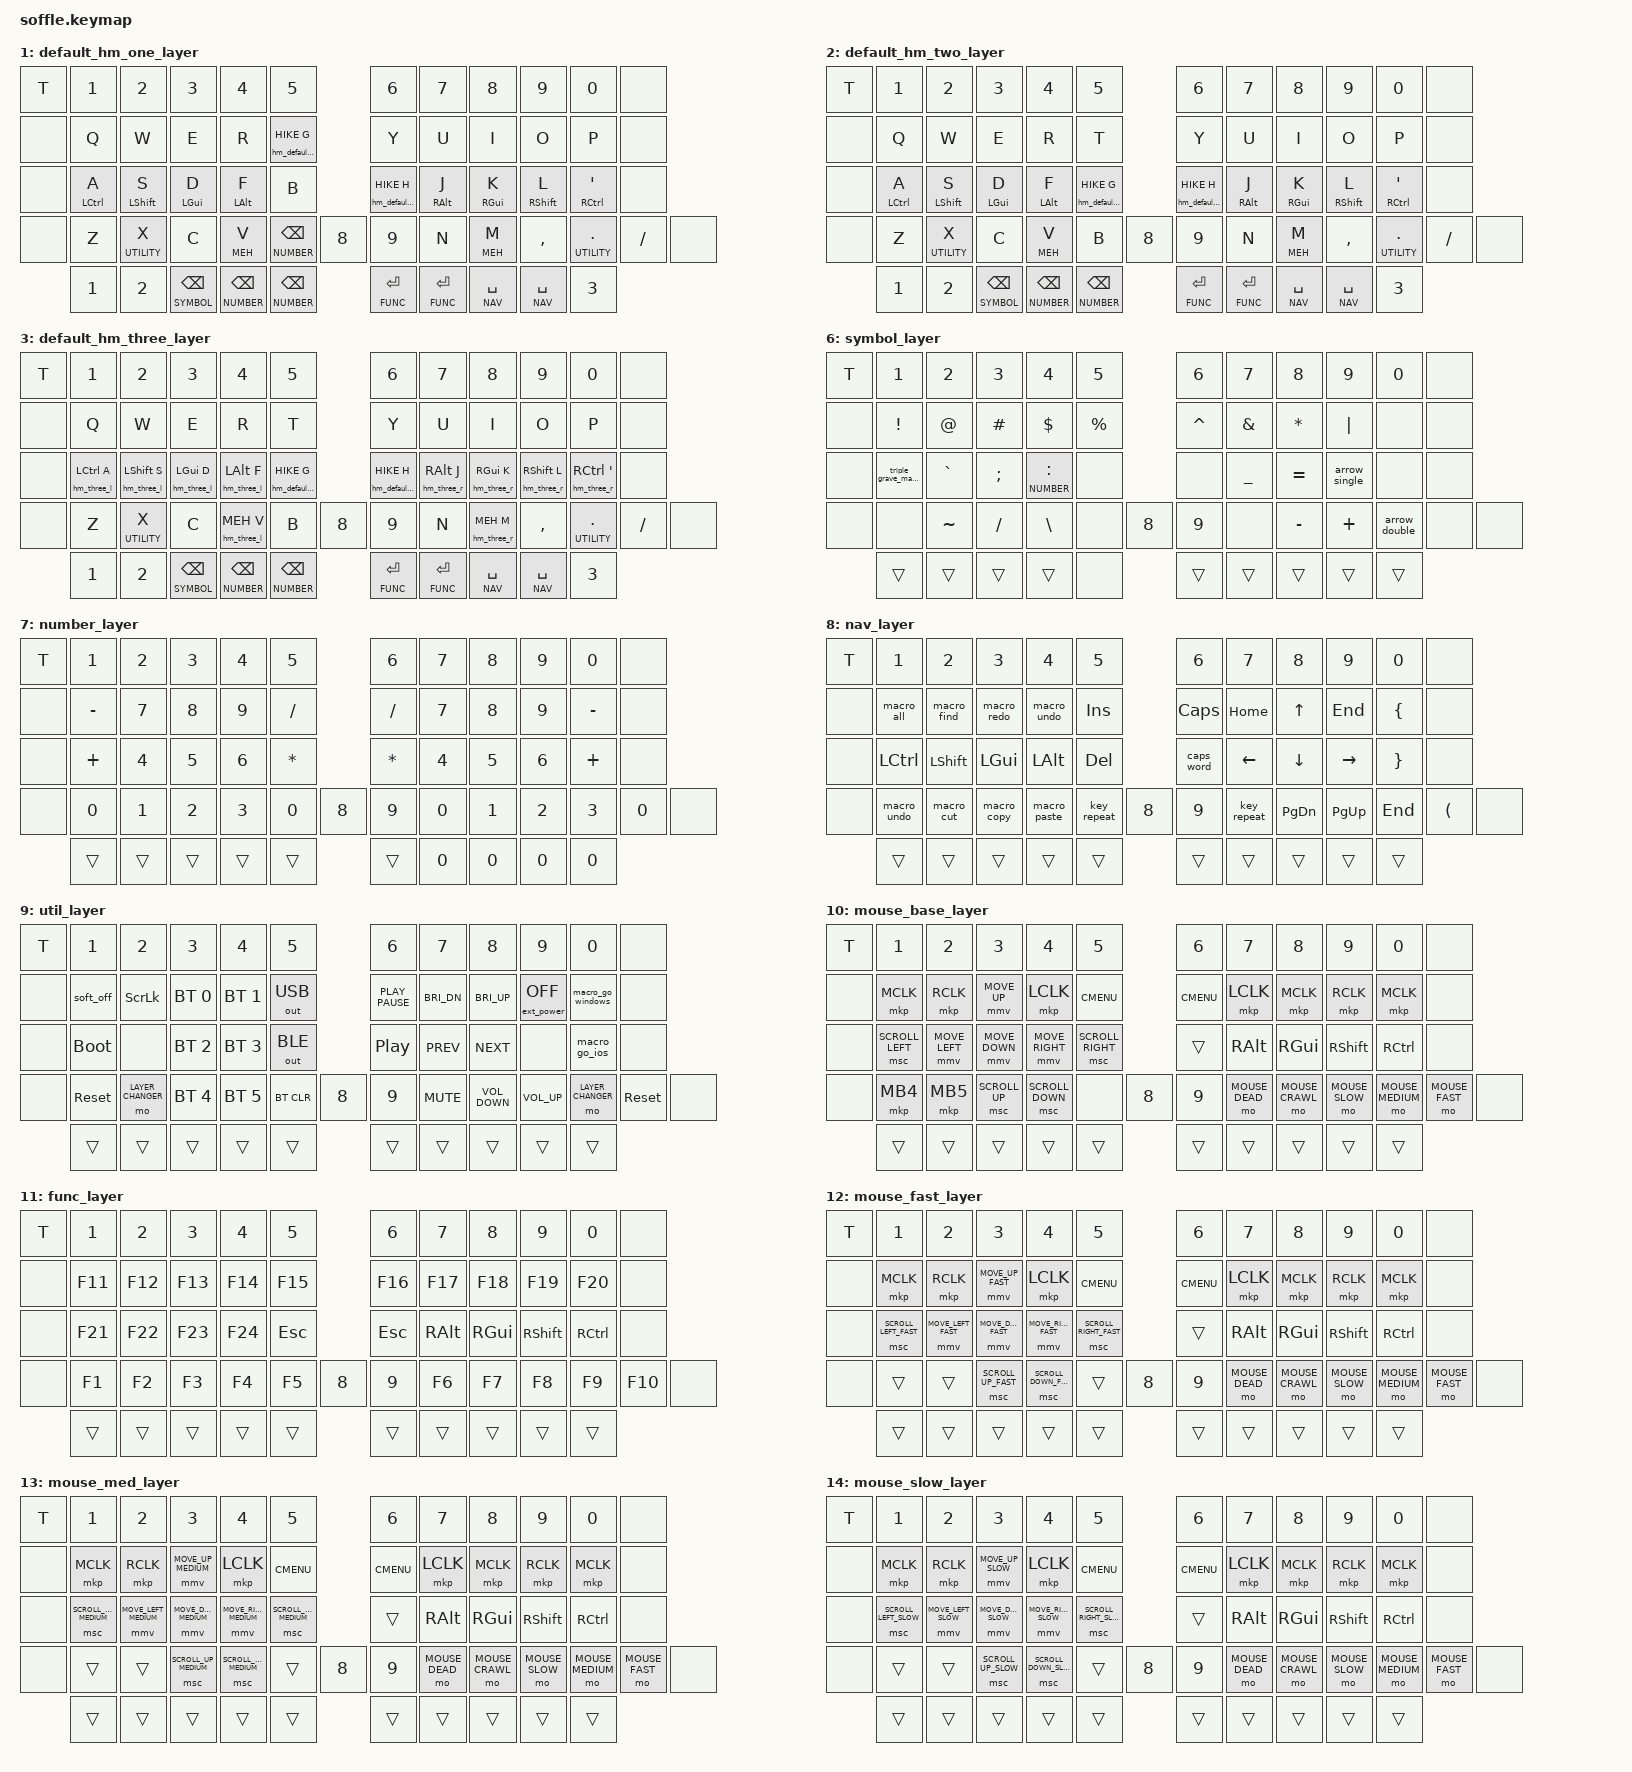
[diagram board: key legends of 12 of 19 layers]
/*
 * Copyright (c) 2020 The ZMK Contributors 
 *
 * SPDX-License-Identifier: MIT
 */

#include <behaviors.dtsi>
#include <behaviors/mouse_keys.dtsi>
#include <dt-bindings/zmk/mouse.h>
#include <dt-bindings/zmk/keys.h>
#include <dt-bindings/zmk/bt.h>
#include <dt-bindings/zmk/outputs.h>
#include <dt-bindings/zmk/ext_power.h>

#include "keymap_mouse.h"
#include "base_configs.h"




/ {
        conditional_layers {
            compatible = "zmk,conditional-layers";
            tri_layer {
                    if-layers = <SYMBOL NAV>;
                    then-layer = <MOUSE_BASE>;
            };
            
             tri_layer_two {
                     if-layers = <FUNC NAV>;
                     then-layer = <CONVENIENCE_LAYER>;
             };

             tri_layer_three {
                     if-layers = <FUNC NUMBER>;
                     then-layer = <CONVENIENCE_LAYER>;
             };
        };

        macros {
            #include "macros.dtsi"
        };
        
        combos {
            #include "combos.dtsi"
        }; 

        behaviors {
            #include "user_behaviors.dtsi"
        };

        keymap {
                compatible = "zmk,keymap";

        default_layer {
                          bindings = < LAYER_FROM64( \
&kp ESCAPE,  &kp B,       &kp N2,       &kp N3,        &kp N4,             &kp N5,                                          &kp N6,             &kp N7,              &kp N8,        &kp N9,       &kp N0,          &kp BACKSPACE,
&kp TAB,     &kp C,        &kp W,        &kp E,         &kp R,              &kp T,                                           &kp Y,              &kp U,               &kp I,         &kp O,        &kp P,           &kp DEL,
&kp LCTRL,   &kp D,  &hrm LALT S,  &hrm LCTRL D,  &hrm LEFT_SHIFT F,  &kp G,                                           &kp H,              &hrm RIGHT_SHIFT J,  &hrm RCTRL K,  &hrm RALT L,  &hrm RGUI SEMI,  &kp SQT,
&kp LSHFT,   &kp Z,        &kp X,        &kp C,         &kp V,              &kp B,          &tog GAME,      &kp C_MUTE,      &kp N,              &kp M,               &kp COMMA,     &kp DOT,      &kp FSLH,        &kp RSHFT,
&kp LCTRL,   &kp LALT,     &trans,       &trans,        &lt NUM ESCAPE,     &lt MOUSE SPACE,&lt MACRO TAB,  &lt SYMBOL ENTER,&lt NAV BACKSPACE,  &lt FUNC DEL,        &trans,        &trans,       &kp F13,         &kp F14
            )>;

            sensor-bindings = <&inc_dec_kp LC(Y) LC(Z) &inc_dec_kp C_VOLUME_UP C_VOL_DN>;
        };

                default_hm_one_layer {												
                        bindings = <											 
        &kp T               	&kp N1              	&kp N2              	&kp N3              	&kp N4              	&kp N5              		                    	&kp N6              	&kp N7              	&kp N8              	&kp N9              	&kp N0              	&none               
        &none               	&kp Q               	&kp W               	&kp E               	&kp R               	&hm_default_l HIKE G		                    	&kp Y               	&kp U               	&kp I               	&kp O               	&kp P               	&none               
        &none               	&hm_one_l LCTRL A   	&hm_one_l LSHFT S   	&hm_one_l LGUI D    	&hm_one_l LALT F    	&kp B               	 	                    	&hm_default_r HIKE H	&hm_one_r RALT J    	&hm_one_r RGUI K    	&hm_one_r RSHFT L   	&hm_one_r RCTRL APOS	&none               
        &none               	&kp Z               	&lt UTILITY X       	&kp C               	&hm_one_l MEH V     	&lt NUMBER BSPC     	&kp N8              	&kp N9              	&kp N               	&hm_one_r MEH M     	&kp COMMA           	&lt UTILITY DOT     	&kp FSLH            	&none               
                                &kp N1              	&kp N2              	&lt SYMBOL BSPC     	&lt NUMBER BSPC     	&lt NUMBER BSPC     		                    	&lt FUNC ENTER      	&lt FUNC ENTER      	&lt NAV SPACE       	&lt NAV SPACE       	&kp N3              	                    
                >; sensor-bindings = <&inc_dec_kp UP DOWN &inc_dec_kp LC(LEFT)  >; };												
                default_hm_two_layer {												
                        bindings = <											
        &kp T               	&kp N1              	&kp N2              	&kp N3              	&kp N4              	&kp N5              		                    	&kp N6              	&kp N7              	&kp N8              	&kp N9              	&kp N0              	&none               
        &none               	&kp Q               	&kp W               	&kp E               	&kp R               	&kp T               		                    	&kp Y               	&kp U               	&kp I               	&kp O               	&kp P               	&none               
        &none               	&hm_two_l LCTRL A   	&hm_two_l LSHFT S   	&hm_two_l LGUI D    	&hm_two_l LALT F    	&hm_default_l HIKE G	  	                    	&hm_default_r HIKE H	&hm_two_r RALT J    	&hm_two_r RGUI K    	&hm_two_r RSHFT L   	&hm_two_r RCTRL APOS	&none               
        &none               	&kp Z               	&lt UTILITY X       	&kp C               	&hm_two_l MEH V     	&kp B               	&kp N8              	&kp N9              	&kp N               	&hm_two_r MEH M     	&kp COMMA           	&lt UTILITY DOT     	&kp FSLH            	&none               
                &kp N1              	&kp N2              	&lt SYMBOL BSPC     	&lt NUMBER BSPC     	&lt NUMBER BSPC     			&lt FUNC ENTER      	&lt FUNC ENTER      	&lt NAV SPACE       	&lt NAV SPACE       	&kp N3              	                    
                >; sensor-bindings = <&inc_dec_kp UP DOWN &inc_dec_kp LC(LEFT)  >; };												
                default_hm_three_layer {												
                        bindings = <											
        &kp T                 	&kp N1                	&kp N2                	&kp N3                	&kp N4                	&kp N5                			&kp N6                	&kp N7                	&kp N8                	&kp N9                	&kp N0                	&none                 
        &none                 	&kp Q                 	&kp W                 	&kp E                 	&kp R                 	&kp T                 			&kp Y                 	&kp U                 	&kp I                 	&kp O                 	&kp P                 	&none                 
        &none                 	&hm_three_l LCTRL A   	&hm_three_l LSHFT S   	&hm_three_l LGUI D    	&hm_three_l LALT F    	&hm_default_l HIKE G  	   	   	&hm_default_r HIKE H  	&hm_three_r RALT J    	&hm_three_r RGUI K    	&hm_three_r RSHFT L   	&hm_three_r RCTRL APOS	&none                 
        &none                 	&kp Z                 	&lt UTILITY X         	&kp C                 	&hm_three_l MEH V     	&kp B                 	&kp N8                	&kp N9                	&kp N                 	&hm_three_r MEH M     	&kp COMMA             	&lt UTILITY DOT       	&kp FSLH              	&none                 
                                &kp N1                	&kp N2                	&lt SYMBOL BSPC       	&lt NUMBER BSPC       	&lt NUMBER BSPC       			&lt FUNC ENTER        	&lt FUNC ENTER        	&lt NAV SPACE         	&lt NAV SPACE         	&kp N3                	                      
                >; sensor-bindings = <&inc_dec_kp UP DOWN &inc_dec_kp LC(LEFT)  >; };												
                default_hm_none_layer {												
                        bindings = <											
        &kp T                	&kp N1               	&kp N2               	&kp N3               	&kp N4               	&kp N5               			&kp N6               	&kp N7               	&kp N8               	&kp N9               	&kp N0               	&none                
                                &kp Q                	&kp W                	&kp E                	&kp R                	&kp T                			&kp Y                	&kp U                	&kp I                	&kp O                	&kp P                	&none                
                                &hm_four_l LCTRL A   	&kp S                	&kp D                	&kp F                	&hm_default_l HIKE G 	    	    	&hm_default_r HIKE H 	&kp J                	&kp K                	&kp L                	&hm_four_r RCTRL APOS	&none                
                                &kp Z                	&lt UTILITY X        	&kp C                	&hm_four_l MEH V     	&kp B                	&kp N8               	&kp N9               	&kp N                	&hm_four_r MEH M     	&kp COMMA            	&lt UTILITY DOT      	&kp FSLH             	&none                
                                &kp N1               	&kp N2               	&lt SYMBOL BSPC      	&lt NUMBER BSPC      	&lt NUMBER BSPC      			&lt FUNC ENTER       	&lt FUNC ENTER       	&lt NAV SPACE        	&lt NAV SPACE        	&kp N3               	                     
                >; sensor-bindings = <&inc_dec_kp UP DOWN &inc_dec_kp LC(LEFT)  >; };												
                default_ios_layer {												
                        bindings = <											
        &kp T                   	&kp N1                  	&kp N2                  	&kp N3                  	&kp N4                  	&kp N5                  			&kp N6                  	&kp N7                  	&kp N8                  	&kp N9                  	&kp N0                  	&none                   
        &none                   	&kp Q                   	&kp W                   	&kp E                   	&kp R                   	&kp T                   			&kp Y                   	&kp U                   	&kp I                   	&kp O                   	&kp P                   	
        &none                   	&hm_default_l LGUI A    	&hm_default_l LSHFT S   	&hm_default_l LCTRL D   	&hm_default_l LALT F    	&hm_default_l HIKE G    	     	     	&hm_default_r HIKE H    	&hm_default_r RALT J    	&hm_default_r RCTRL K   	&hm_default_r RSHFT L   	&hm_default_r RGUI APOS 	
        &none                   	&hm_default_l LSHFT Z   	&lt UTILITY X           	&kp C                   	&hm_default_l MEH V     	&kp B                   	&kp N8                  	&kp N9                  	&kp N                   	&hm_default_r MEH M     	&kp COMMA               	&lt UTILITY DOT         	&hm_default_r LSHFT FSLH	
                                        &kp N1                  	&kp N2                  	&lt SYMBOL BSPC         	&lt NUMBER BSPC         	&lt NUMBER BSPC         			&lt FUNC ENTER          	&lt FUNC ENTER          	&lt NAV SPACE           	&lt NAV SPACE           	&kp N3                  	
                >; sensor-bindings = <&inc_dec_kp UP DOWN &inc_dec_kp LC(LEFT)  >; };												
                symbol_layer {												
                        bindings = <											
        &kp T              	&kp N1             	&kp N2             	&kp N3             	&kp N4             	&kp N5             			&kp N6             	&kp N7             	&kp N8             	&kp N9             	&kp N0             	&none              
        &none              	&kp EXCL           	&kp AT             	&kp HASH           	&kp DOLLAR         	&kp PERCENT        			&kp CARET          	&kp AMPS           	&kp STAR           	&kp PIPE           	&none              	&none              
        &none              	&triple_grave_macro	&kp GRAVE          	&kp SEMI           	&lt NUMBER COLON   	&none              	     	     	&none              	&kp UNDER          	&kp EQUAL          	&arrow_single      	&none              	&none              
        &none              	&none              	&kp TILDE          	&kp FSLH           	&kp BSLH           	&none              	&kp N8             	&kp N9             	&none              	&kp MINUS          	&kp PLUS           	&arrow_double      	&none              	&none              
                                &trans             	&trans             	&trans             	&trans             	&none              			&trans             	&trans             	&trans             	&trans             	&trans             	                   
                >; sensor-bindings = <&inc_dec_kp UP DOWN &inc_dec_kp LC(LEFT)  >; };												
                number_layer {												
                        bindings = <											
        &kp T    	&kp N1   	&kp N2   	&kp N3   	&kp N4   	&kp N5   			&kp N6   	&kp N7   	&kp N8   	&kp N9   	&kp N0   	&none    
        &none    	&kp MINUS	&kp N7   	&kp N8   	&kp N9   	&kp FSLH 			&kp FSLH 	&kp N7   	&kp N8   	&kp N9   	&kp MINUS	&none    
        &none    	&kp PLUS 	&kp N4   	&kp N5   	&kp N6   	&kp STAR 	      	      	&kp STAR 	&kp N4   	&kp N5   	&kp N6   	&kp PLUS 	&none    
        &none    	&kp N0   	&kp N1   	&kp N2   	&kp N3   	&kp N0   	&kp N8   	&kp N9   	&kp N0   	&kp N1   	&kp N2   	&kp N3   	&kp N0   	&none    
                        &trans   	&trans   	&trans   	&trans   	&trans   			&trans   	&kp N0   	&kp N0   	&kp N0   	&kp N0   	         
                >; sensor-bindings = <&inc_dec_kp UP DOWN &inc_dec_kp LC(LEFT)  >; };												
                nav_layer {												
                        bindings = <											
        &kp T       	&kp N1      	&kp N2      	&kp N3      	&kp N4      	&kp N5      			&kp N6      	&kp N7      	&kp N8      	&kp N9      	&kp N0      	&none       
        &none       	&macro_all  	&macro_find 	&macro_redo 	&macro_undo 	&kp INS     			&kp CAPS    	&kp HOME    	&kp UP      	&kp END     	&kp LBRC    	&none       
        &none       	&kp LCTRL   	&kp LSHFT   	&kp LGUI    	&kp LALT    	&kp DEL     	       	       	&caps_word  	&kp LEFT    	&kp DOWN    	&kp RIGHT   	&kp RBRC    	&none       
        &none       	&macro_undo 	&macro_cut  	&macro_copy 	&macro_paste	&key_repeat 	&kp N8      	&kp N9      	&key_repeat 	&kp PG_DN   	&kp PG_UP   	&kp END     	&kp LPAR    	&none       
                        &trans      	&trans      	&trans      	&trans      	&trans      			&trans      	&trans      	&trans      	&trans      	&trans      	            
                >; sensor-bindings = <&inc_dec_kp UP DOWN &inc_dec_kp LC(LEFT)  >; };												
                util_layer {												
                        bindings = <											
        &kp T            	&kp N1           	&kp N2           	&kp N3           	&kp N4           	&kp N5           			&kp N6           	&kp N7           	&kp N8           	&kp N9           	&kp N0           	&none            
        &none            	&soft_off        	&kp SLCK         	&bt BT_SEL 0     	&bt BT_SEL 1     	&out OUT_USB     			&kp K_PLAY_PAUSE 	&kp C_BRI_DN     	&kp C_BRI_UP     	&ext_power EP_OFF	&macro_go_windows	&none            
        &none            	&bootloader      	&none            	&bt BT_SEL 2     	&bt BT_SEL 3     	&out OUT_BLE     	        	        	&kp C_PLAY_PAUSE 	&kp C_PREV       	&kp C_NEXT       	&none            	&macro_go_ios    	&none            
        &none            	&sys_reset       	&mo LAYER_CHANGER	&bt BT_SEL 4     	&bt BT_SEL 5     	&bt BT_CLR       	&kp N8           	&kp N9           	&kp C_MUTE       	&kp C_VOLUME_DOWN	&kp C_VOLUME_UP  	&mo LAYER_CHANGER	&sys_reset       	&none            
                                &trans           	&trans           	&trans           	&trans           	&trans           			&trans           	&trans           	&trans           	&trans           	&trans           	                 
                >; sensor-bindings = <&inc_dec_kp UP DOWN &inc_dec_kp LC(LEFT)  >; };												
                mouse_base_layer {												
                        bindings = <											
        &kp T            	&kp N1           	&kp N2           	&kp N3           	&kp N4           	&kp N5           			&kp N6           	&kp N7           	&kp N8           	&kp N9           	&kp N0           	&none            
        &none            	&mkp MCLK        	&mkp RCLK        	&mmv MOVE_UP     	&mkp LCLK        	&kp K_CMENU      			&kp K_CMENU      	&mkp LCLK        	&mkp MCLK        	&mkp RCLK        	&mkp MCLK        	&none            
        &none            	&msc SCROLL_LEFT 	&mmv MOVE_LEFT   	&mmv MOVE_DOWN   	&mmv MOVE_RIGHT  	&msc SCROLL_RIGHT	         	         	&trans           	&kp RALT         	&kp RGUI         	&kp RSHFT        	&kp RCTRL        	&none            
        &none            	&mkp MB4         	&mkp MB5         	&msc SCROLL_UP   	&msc SCROLL_DOWN 	&none            	&kp N8           	&kp N9           	&mo MOUSE_DEAD   	&mo MOUSE_CRAWL  	&mo MOUSE_SLOW   	&mo MOUSE_MEDIUM 	&mo MOUSE_FAST   	&none            
                                &trans           	&trans           	&trans           	&trans           	&trans           			&trans           	&trans           	&trans           	&trans           	&trans           	                 
                >; sensor-bindings = <&inc_dec_kp UP DOWN &inc_dec_kp LC(LEFT)  >; };												
                func_layer {												
                        bindings = <											
        &kp T    	&kp N1   	&kp N2   	&kp N3   	&kp N4   	&kp N5   			&kp N6   	&kp N7   	&kp N8   	&kp N9   	&kp N0   	&none    
        &none    	&kp F11  	&kp F12  	&kp F13  	&kp F14  	&kp F15  			&kp F16  	&kp F17  	&kp F18  	&kp F19  	&kp F20  	&none    
        &none    	&kp F21  	&kp F22  	&kp F23  	&kp F24  	&kp ESC  	          	          	&kp ESC  	&kp RALT 	&kp RGUI 	&kp RSHFT	&kp RCTRL	&none    
        &none    	&kp F1   	&kp F2   	&kp F3   	&kp F4   	&kp F5   	&kp N8   	&kp N9   	&kp F6   	&kp F7   	&kp F8   	&kp F9   	&kp F10  	&none    
                        &trans   	&trans   	&trans   	&trans   	&trans   			&trans   	&trans   	&trans   	&trans   	&trans   	         
                >; sensor-bindings = <&inc_dec_kp UP DOWN &inc_dec_kp LC(LEFT)  >; };												
                mouse_fast_layer {												
                        bindings = <											
        &kp T                 	&kp N1                	&kp N2                	&kp N3                	&kp N4                	&kp N5                			&kp N6                	&kp N7                	&kp N8                	&kp N9                	&kp N0                	&none                 
        &none                 	&mkp MCLK             	&mkp RCLK             	&mmv MOVE_UP_FAST     	&mkp LCLK             	&kp K_CMENU           			&kp K_CMENU           	&mkp LCLK             	&mkp MCLK             	&mkp RCLK             	&mkp MCLK             	&none                 
        &none                 	&msc SCROLL_LEFT_FAST 	&mmv MOVE_LEFT_FAST   	&mmv MOVE_DOWN_FAST   	&mmv MOVE_RIGHT_FAST  	&msc SCROLL_RIGHT_FAST	           	           	&trans                	&kp RALT              	&kp RGUI              	&kp RSHFT             	&kp RCTRL             	&none                 
        &none                 	&trans                	&trans                	&msc SCROLL_UP_FAST   	&msc SCROLL_DOWN_FAST 	&trans                	&kp N8                	&kp N9                	&mo MOUSE_DEAD        	&mo MOUSE_CRAWL       	&mo MOUSE_SLOW        	&mo MOUSE_MEDIUM      	&mo MOUSE_FAST        	&none                 
                                &trans                	&trans                	&trans                	&trans                	&trans                			&trans                	&trans                	&trans                	&trans                	&trans                	                      
                >; sensor-bindings = <&inc_dec_kp UP DOWN &inc_dec_kp LC(LEFT)  >; };												
                mouse_med_layer {												
                        bindings = <											
        &kp T                   	&kp N1                  	&kp N2                  	&kp N3                  	&kp N4                  	&kp N5                  			&kp N6                  	&kp N7                  	&kp N8                  	&kp N9                  	&kp N0                  	&none                   
        &none                   	&mkp MCLK               	&mkp RCLK               	&mmv MOVE_UP_MEDIUM     	&mkp LCLK               	&kp K_CMENU             			&kp K_CMENU             	&mkp LCLK               	&mkp MCLK               	&mkp RCLK               	&mkp MCLK               	&none                   
        &none                   	&msc SCROLL_LEFT_MEDIUM 	&mmv MOVE_LEFT_MEDIUM   	&mmv MOVE_DOWN_MEDIUM   	&mmv MOVE_RIGHT_MEDIUM  	&msc SCROLL_RIGHT_MEDIUM	            	            	&trans                  	&kp RALT                	&kp RGUI                	&kp RSHFT               	&kp RCTRL               	&none                   
        &none                   	&trans                  	&trans                  	&msc SCROLL_UP_MEDIUM   	&msc SCROLL_DOWN_MEDIUM 	&trans                  	&kp N8                  	&kp N9                  	&mo MOUSE_DEAD          	&mo MOUSE_CRAWL         	&mo MOUSE_SLOW          	&mo MOUSE_MEDIUM        	&mo MOUSE_FAST          	&none                   
                                        &trans                  	&trans                  	&trans                  	&trans                  	&trans                  			&trans                  	&trans                  	&trans                  	&trans                  	&trans                  	                        
                >; sensor-bindings = <&inc_dec_kp UP DOWN &inc_dec_kp LC(LEFT)  >; };												
                mouse_slow_layer {												
                        bindings = <											
        &kp T                 	&kp N1                	&kp N2                	&kp N3                	&kp N4                	&kp N5                			&kp N6                	&kp N7                	&kp N8                	&kp N9                	&kp N0                	&none                 
        &none                 	&mkp MCLK             	&mkp RCLK             	&mmv MOVE_UP_SLOW     	&mkp LCLK             	&kp K_CMENU           			&kp K_CMENU           	&mkp LCLK             	&mkp MCLK             	&mkp RCLK             	&mkp MCLK             	&none                 
        &none                 	&msc SCROLL_LEFT_SLOW 	&mmv MOVE_LEFT_SLOW   	&mmv MOVE_DOWN_SLOW   	&mmv MOVE_RIGHT_SLOW  	&msc SCROLL_RIGHT_SLOW	             	             	&trans                	&kp RALT              	&kp RGUI              	&kp RSHFT             	&kp RCTRL             	&none                 
        &none                 	&trans                	&trans                	&msc SCROLL_UP_SLOW   	&msc SCROLL_DOWN_SLOW 	&trans                	&kp N8                	&kp N9                	&mo MOUSE_DEAD        	&mo MOUSE_CRAWL       	&mo MOUSE_SLOW        	&mo MOUSE_MEDIUM      	&mo MOUSE_FAST        	&none                 
                                &trans                	&trans                	&trans                	&trans                	&trans                			&trans                	&trans                	&trans                	&trans                	&trans                	                      
                >; sensor-bindings = <&inc_dec_kp UP DOWN &inc_dec_kp LC(LEFT)  >; };												
                mouse_crawl_layer {												
                        bindings = <											
        &kp T                  	&kp N1                 	&kp N2                 	&kp N3                 	&kp N4                 	&kp N5                 			&kp N6                 	&kp N7                 	&kp N8                 	&kp N9                 	&kp N0                 	&none                  
        &none                  	&mkp MCLK              	&mkp RCLK              	&mmv MOVE_UP_CRAWL     	&mkp LCLK              	&kp K_CMENU            			&kp K_CMENU            	&mkp LCLK              	&mkp MCLK              	&mkp RCLK              	&mkp MCLK              	&none                  
        &none                  	&msc SCROLL_LEFT_CRAWL 	&mmv MOVE_LEFT_CRAWL   	&mmv MOVE_DOWN_CRAWL   	&mmv MOVE_RIGHT_CRAWL  	&msc SCROLL_RIGHT_CRAWL	              	              	&trans                 	&kp RALT               	&kp RGUI               	&kp RSHFT              	&kp RCTRL              	&none                  
        &none                  	&trans                 	&trans                 	&msc SCROLL_UP_CRAWL   	&msc SCROLL_DOWN_CRAWL 	&trans                 	&kp N8                 	&kp N9                 	&mo MOUSE_DEAD         	&mo MOUSE_CRAWL        	&mo MOUSE_SLOW         	&mo MOUSE_MEDIUM       	&mo MOUSE_FAST         	&none                  
                                &trans                 	&trans                 	&trans                 	&trans                 	&trans                 			&trans                 	&trans                 	&trans                 	&trans                 	&trans                 	                       
                >; sensor-bindings = <&inc_dec_kp UP DOWN &inc_dec_kp LC(LEFT)  >; };												
                mouse_dead_layer {												
                        bindings = <											
        &kp T                  	&kp N1                 	&kp N2                 	&kp N3                 	&kp N4                 	&kp N5                 			&kp N6                 	&kp N7                 	&kp N8                 	&kp N9                 	&kp N0                 	&none                  
        &none                  	&mkp MCLK              	&mkp RCLK              	&mmv MOVE_UP_CRAWL     	&mkp LCLK              	&kp K_CMENU            			&kp K_CMENU            	&mkp LCLK              	&mkp MCLK              	&mkp RCLK              	&mkp MCLK              	&none                  
        &none                  	&msc SCROLL_LEFT_CRAWL 	&mmv MOVE_LEFT_CRAWL   	&mmv MOVE_DOWN_CRAWL   	&mmv MOVE_RIGHT_CRAWL  	&msc SCROLL_RIGHT_CRAWL	               	               	&trans                 	&kp RALT               	&kp RGUI               	&kp RSHFT              	&kp RCTRL              	&none                  
        &none                  	&trans                 	&trans                 	&msc SCROLL_UP_CRAWL   	&msc SCROLL_DOWN_CRAWL 	&trans                 	&kp N8                 	&kp N9                 	&mo MOUSE_DEAD         	&mo MOUSE_CRAWL        	&mo MOUSE_SLOW         	&mo MOUSE_MEDIUM       	&mo MOUSE_FAST         	&none                  
                                &trans                 	&trans                 	&trans                 	&trans                 	&trans                 			&trans                 	&trans                 	&trans                 	&trans                 	&trans                 	                       
                >; sensor-bindings = <&inc_dec_kp UP DOWN &inc_dec_kp LC(LEFT)  >; };												
                convenience_layer {												
                        bindings = <											
        &kp T                  	&kp N1                 	&kp N2                 	&kp N3                 	&kp N4                 	&kp N5                 			&kp N6                 	&kp N7                 	&kp N8                 	&kp N9                 	&kp N0                 	&none                  
        &none                  	&none                  	&surround_brace        	&surround_paran        	&surround_bracket      	&git_add               			&git_add_i_hunk        	&macro_jira_issue      	&none                  	&none                  	&none                  	&none                  
        &none                  	&git_clean_n           	&git_diff_cached       	&git_reflog            	&git_status            	&git_commit            	                	                	&git_commit_amend      	&none                  	&none                  	&none                  	&none                  	&none                  
        &none                  	&none                  	&none                  	&git_merged_list       	&git_no_merged_list    	&git_push              	&kp N8                 	&kp N9                 	&git_checkout_switch   	&git_branch_commit_list	&none                  	&none                  	&none                  	&none                  
                                &trans                 	&trans                 	&trans                 	&trans                 	&trans                 			&trans                 	&trans                 	&trans                 	&trans                 	&trans                 	                       
                >; sensor-bindings = <&inc_dec_kp UP DOWN &inc_dec_kp LC(LEFT)  >; };												
                layer_changer_layer {												
                        bindings = <											
        &kp T               	&kp N1              	&kp N2              	&kp N3              	&kp N4              	&kp N5              			&kp N6              	&kp N7              	&kp N8              	&kp N9              	&kp N0              	&none               
        &none               	&none               	&none               	&to DEFAULT_HM_TWO  	&to DEFAULT_HM_ONE  	&to DEFAULT_HM      			&to DEFAULT_HM      	&to DEFAULT_HM_ONE  	&to DEFAULT_HM_TWO  	&none               	&none               	&none               
        &none               	&none               	&none               	&to DEFAULT_HM_NONE 	&to DEFAULT_HM_THREE	&to DEFAULT_IOS     	                 	                 	&to DEFAULT_IOS     	&to DEFAULT_HM_THREE	&to DEFAULT_HM_NONE 	&none               	&none               	&none               
        &none               	&none               	&none               	&none               	&none               	&none               	&kp N8              	&kp N9              	&none               	&none               	&none               	&none               	&none               	&none               
                                &trans              	&trans              	&trans              	&trans              	&trans              			&trans              	&trans              	&trans              	&trans              	&trans              	                    
                >; sensor-bindings = <&inc_dec_kp UP DOWN &inc_dec_kp LC(LEFT)  >; };												

        };
 };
